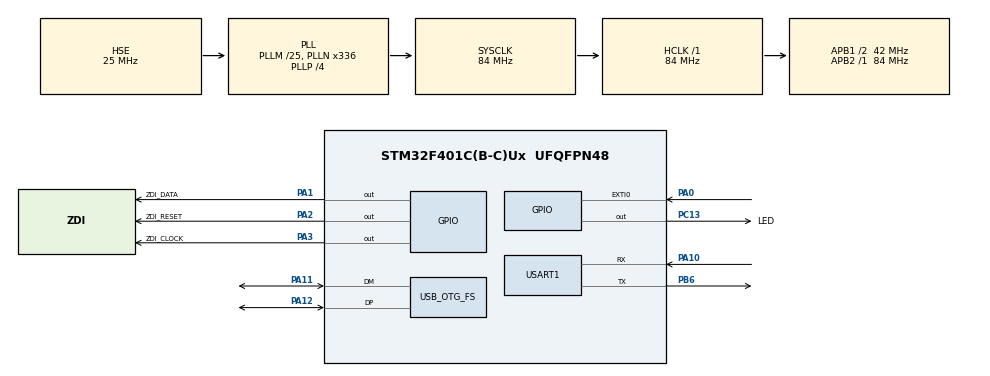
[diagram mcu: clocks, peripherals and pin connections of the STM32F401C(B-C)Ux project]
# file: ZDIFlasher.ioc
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Mcu.Family=STM32F4
Mcu.Name=STM32F401C(B-C)Ux
Mcu.Package=UFQFPN48
NVIC.EXTI0_IRQn=true\:0\:0\:false\:false\:true\:true\:true\:true
NVIC.OTG_FS_IRQn=true\:0\:0\:false\:false\:true\:true\:true\:true
NVIC.PriorityGroup=NVIC_PRIORITYGROUP_4
PA0-WKUP.GPIO_PuPd=GPIO_PULLUP
PA0-WKUP.Signal=GPXTI0
PA1.GPIO_Label=ZDI_DATA
PA1.GPIO_ModeDefaultOutputPP=GPIO_MODE_OUTPUT_PP
PA1.GPIO_PuPd=GPIO_NOPULL
PA1.GPIO_Speed=GPIO_SPEED_FREQ_VERY_HIGH
PA1.PinState=GPIO_PIN_SET
PA1.Signal=GPIO_Output
PA10.Mode=Asynchronous
PA10.Signal=USART1_RX
PA11.Mode=Device_Only
PA11.Signal=USB_OTG_FS_DM
PA12.Mode=Device_Only
PA12.Signal=USB_OTG_FS_DP
PA2.GPIO_Label=ZDI_RESET
PA2.GPIO_ModeDefaultOutputPP=GPIO_MODE_OUTPUT_OD
PA2.GPIO_PuPd=GPIO_NOPULL
PA2.GPIO_Speed=GPIO_SPEED_FREQ_VERY_HIGH
PA2.PinState=GPIO_PIN_SET
PA2.Signal=GPIO_Output
PA3.GPIO_Label=ZDI_CLOCK
PA3.GPIO_ModeDefaultOutputPP=GPIO_MODE_OUTPUT_PP
PA3.GPIO_PuPd=GPIO_NOPULL
PA3.GPIO_Speed=GPIO_SPEED_FREQ_VERY_HIGH
PA3.PinState=GPIO_PIN_SET
PA3.Signal=GPIO_Output
PB6.Mode=Asynchronous
PB6.Signal=USART1_TX
PC13-ANTI_TAMP.GPIO_Label=LED
PC13-ANTI_TAMP.GPIO_ModeDefaultOutputPP=GPIO_MODE_OUTPUT_PP
PC13-ANTI_TAMP.GPIO_PuPd=GPIO_NOPULL
PC13-ANTI_TAMP.PinState=GPIO_PIN_SET
PC13-ANTI_TAMP.Signal=GPIO_Output
PC14-OSC32_IN.Mode=LSE-External-Oscillator
PC14-OSC32_IN.Signal=RCC_OSC32_IN
PC15-OSC32_OUT.Mode=LSE-External-Oscillator
PC15-OSC32_OUT.Signal=RCC_OSC32_OUT
PH0\ -\ OSC_IN.Mode=HSE-External-Oscillator
PH0\ -\ OSC_IN.Signal=RCC_OSC_IN
PH1\ -\ OSC_OUT.Mode=HSE-External-Oscillator
PH1\ -\ OSC_OUT.Signal=RCC_OSC_OUT
ProjectManager.HeapSize=0x200
ProjectManager.StackSize=0x400
ProjectManager.TargetToolchain=STM32CubeIDE
RCC.48MHZClocksFreq_Value=48000000
RCC.AHBFreq_Value=84000000
RCC.APB1CLKDivider=RCC_HCLK_DIV2
RCC.APB1Freq_Value=42000000
RCC.APB1TimFreq_Value=84000000
RCC.APB2Freq_Value=84000000
RCC.APB2TimFreq_Value=84000000
RCC.CortexFreq_Value=84000000
RCC.HCLKFreq_Value=84000000
RCC.HSE_VALUE=25000000
RCC.HSI_VALUE=16000000
RCC.PLLI2SN=384
RCC.PLLM=25
RCC.PLLN=336
RCC.PLLP=RCC_PLLP_DIV4
RCC.PLLQ=7
RCC.SYSCLKFreq_VALUE=84000000
RCC.SYSCLKSource=RCC_SYSCLKSOURCE_PLLCLK
RCC.VCOOutputFreq_Value=336000000
USART1.VirtualMode=VM_ASYNC
USB_DEVICE.CLASS_NAME_FS=CDC
USB_DEVICE.VirtualMode=Cdc
USB_DEVICE.VirtualModeFS=Cdc_FS
USB_OTG_FS.Sof_enable=DISABLE
USB_OTG_FS.VirtualMode=Device_Only
USB_OTG_FS.lpm_enable=DISABLE
VP_USB_DEVICE_VS_USB_DEVICE_CDC_FS.Mode=CDC_FS
board=custom

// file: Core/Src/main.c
/* USER CODE BEGIN Header */
/**
  ******************************************************************************
  * @file           : main.c
  * @brief          : Main program body
  ******************************************************************************
  * @attention
  *
  * Copyright (c) 2023 STMicroelectronics.
  * All rights reserved.
  *
  * This software is licensed under terms that can be found in the LICENSE file
  * in the root directory of this software component.
  * If no LICENSE file comes with this software, it is provided AS-IS.
  *
  ******************************************************************************
  */
/* USER CODE END Header */
#include "main.h"
#include "usart.h"
#include "usb_device.h"
#include "gpio.h"

/* USER CODE BEGIN Includes */
#include "app_zdi.h"

/* USER CODE END Includes */

void SystemClock_Config(void);

int main(void)
{

  /* MCU Configuration--------------------------------------------------------*/

  /* Reset of all peripherals, Initializes the Flash interface and the Systick. */
  HAL_Init();

  /* Configure the system clock */
  SystemClock_Config();

  /* Initialize all configured peripherals */
  MX_GPIO_Init();
  MX_USB_DEVICE_Init();
  MX_USART1_UART_Init();
  /* USER CODE BEGIN 2 */

  app_zdi_init();

  /* USER CODE END 2 */

  /* Infinite loop */
  /* USER CODE BEGIN WHILE */
  while (1)
  {
	  app_zdi_loop();

    /* USER CODE END WHILE */

  }
}

void SystemClock_Config(void)
{
  RCC_OscInitTypeDef RCC_OscInitStruct = {0};
  RCC_ClkInitTypeDef RCC_ClkInitStruct = {0};

  /** Configure the main internal regulator output voltage
  */
  __HAL_RCC_PWR_CLK_ENABLE();
  __HAL_PWR_VOLTAGESCALING_CONFIG(PWR_REGULATOR_VOLTAGE_SCALE2);

  /** Initializes the RCC Oscillators according to the specified parameters
  * in the RCC_OscInitTypeDef structure.
  */
  RCC_OscInitStruct.OscillatorType = RCC_OSCILLATORTYPE_HSE;
  RCC_OscInitStruct.HSEState = RCC_HSE_ON;
  RCC_OscInitStruct.PLL.PLLState = RCC_PLL_ON;
  RCC_OscInitStruct.PLL.PLLSource = RCC_PLLSOURCE_HSE;
  RCC_OscInitStruct.PLL.PLLM = 25;
  RCC_OscInitStruct.PLL.PLLN = 336;
  RCC_OscInitStruct.PLL.PLLP = RCC_PLLP_DIV4;
  RCC_OscInitStruct.PLL.PLLQ = 7;
  if (HAL_RCC_OscConfig(&RCC_OscInitStruct) != HAL_OK)
  {
    Error_Handler();
  }

  /** Initializes the CPU, AHB and APB buses clocks
  */
  RCC_ClkInitStruct.ClockType = RCC_CLOCKTYPE_HCLK|RCC_CLOCKTYPE_SYSCLK
                              |RCC_CLOCKTYPE_PCLK1|RCC_CLOCKTYPE_PCLK2;
  RCC_ClkInitStruct.SYSCLKSource = RCC_SYSCLKSOURCE_PLLCLK;
  RCC_ClkInitStruct.AHBCLKDivider = RCC_SYSCLK_DIV1;
  RCC_ClkInitStruct.APB1CLKDivider = RCC_HCLK_DIV2;
  RCC_ClkInitStruct.APB2CLKDivider = RCC_HCLK_DIV1;

  if (HAL_RCC_ClockConfig(&RCC_ClkInitStruct, FLASH_LATENCY_2) != HAL_OK)
  {
    Error_Handler();
  }
}

/* USER CODE BEGIN 4 */
/**
  * @brief  Retargets the C library printf function to the USART.
  * @param  None
  * @retval None
  */
int __io_putchar(int ch)
{
  /* Place your implementation of fputc here */
  /* e.g. write a character to the USART1 and Loop until the end of transmission */
  HAL_UART_Transmit(&huart1, (uint8_t *)&ch, 1, 0xFFFF);

  return ch;
}

/* USER CODE END 4 */

void Error_Handler(void)
{
  __disable_irq();
  while (1)
  {
  }
}
